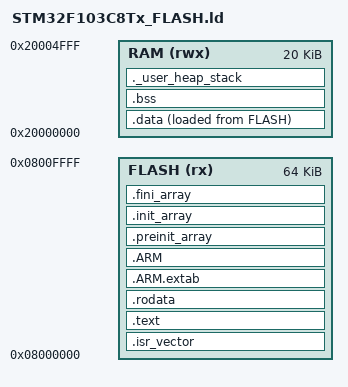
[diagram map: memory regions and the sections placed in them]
/* STM32F103C8Tx_FLASH.ld
 * Linker script for STM32F103C8T6 (Blue Pill).
 *
 *   Flash : 64 KiB @ 0x08000000
 *   RAM   : 20 KiB @ 0x20000000
 */

ENTRY(Reset_Handler)

_estack = ORIGIN(RAM) + LENGTH(RAM);   /* initial stack pointer = top of RAM */

MEMORY
{
  FLASH (rx)  : ORIGIN = 0x08000000, LENGTH = 64K
  RAM   (rwx) : ORIGIN = 0x20000000, LENGTH = 20K
}

SECTIONS
{
  /* ── Vector table: must be the very first thing in flash ──────────────── */
  .isr_vector :
  {
    . = ALIGN(4);
    KEEP(*(.isr_vector))
    . = ALIGN(4);
  } >FLASH

  /* ── Code and read-only data ──────────────────────────────────────────── */
  .text :
  {
    . = ALIGN(4);
    *(.text)
    *(.text*)
    *(.glue_7)
    *(.glue_7t)
    KEEP(*(.init))
    KEEP(*(.fini))
    . = ALIGN(4);
    _etext = .;
  } >FLASH

  .rodata :
  {
    . = ALIGN(4);
    *(.rodata)
    *(.rodata*)
    . = ALIGN(4);
  } >FLASH

  .ARM.extab : { *(.ARM.extab* .gnu.linkonce.armextab.*) } >FLASH

  .ARM :
  {
    __exidx_start = .;
    *(.ARM.exidx*)
    __exidx_end = .;
  } >FLASH

  /* C++ static-constructor / destructor tables */
  .preinit_array :
  {
    PROVIDE_HIDDEN(__preinit_array_start = .);
    KEEP(*(.preinit_array*))
    PROVIDE_HIDDEN(__preinit_array_end = .);
  } >FLASH

  .init_array :
  {
    PROVIDE_HIDDEN(__init_array_start = .);
    KEEP(*(SORT(.init_array.*)))
    KEEP(*(.init_array*))
    PROVIDE_HIDDEN(__init_array_end = .);
  } >FLASH

  .fini_array :
  {
    PROVIDE_HIDDEN(__fini_array_start = .);
    KEEP(*(SORT(.fini_array.*)))
    KEEP(*(.fini_array*))
    PROVIDE_HIDDEN(__fini_array_end = .);
  } >FLASH

  /* ── Initialised data: stored in flash, copied to RAM at reset ────────── */
  _sidata = LOADADDR(.data);

  .data :
  {
    . = ALIGN(4);
    _sdata = .;
    *(.data)
    *(.data*)
    . = ALIGN(4);
    _edata = .;
  } >RAM AT> FLASH

  /* ── Zero-initialised data ────────────────────────────────────────────── */
  .bss :
  {
    . = ALIGN(4);
    _sbss = .;
    *(.bss)
    *(.bss*)
    *(COMMON)
    . = ALIGN(4);
    _ebss = .;
  } >RAM

  /* ── Sanity check: reserve space for a minimal heap + stack ──────────── */
  ._user_heap_stack :
  {
    . = ALIGN(8);
    PROVIDE(end = .);
    . = . + 0x200;   /* 512 B minimum heap  */
    . = . + 0x400;   /* 1 KiB minimum stack */
    . = ALIGN(8);
  } >RAM
}
